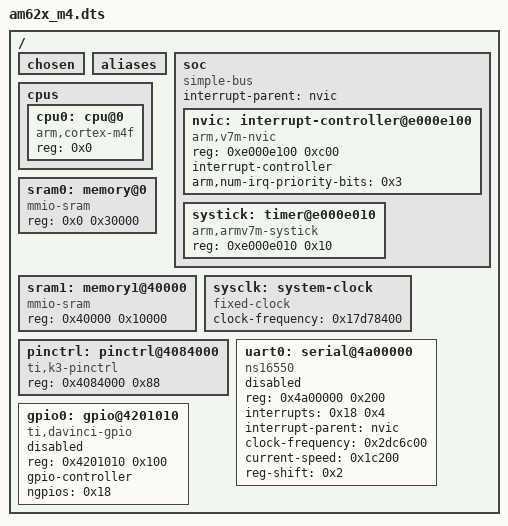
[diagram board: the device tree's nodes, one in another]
/dts-v1/;

/ {
	#address-cells = < 0x1 >;
	#size-cells = < 0x1 >;
	chosen {
	};
	aliases {
	};
	soc {
		#address-cells = < 0x1 >;
		#size-cells = < 0x1 >;
		compatible = "simple-bus";
		interrupt-parent = < &nvic >;
		ranges;
		nvic: interrupt-controller@e000e100 {
			#address-cells = < 0x1 >;
			compatible = "arm,v7m-nvic";
			reg = < 0xe000e100 0xc00 >;
			interrupt-controller;
			#interrupt-cells = < 0x2 >;
			arm,num-irq-priority-bits = < 0x3 >;
			phandle = < 0x1 >;
		};
		systick: timer@e000e010 {
			compatible = "arm,armv7m-systick";
			reg = < 0xe000e010 0x10 >;
			status = "okay";
		};
	};
	cpus {
		#address-cells = < 0x1 >;
		#size-cells = < 0x0 >;
		cpu0: cpu@0 {
			device_type = "cpu";
			compatible = "arm,cortex-m4f";
			reg = < 0x0 >;
		};
	};
	sram0: memory@0 {
		compatible = "mmio-sram";
		reg = < 0x0 0x30000 >;
	};
	sram1: memory1@40000 {
		compatible = "mmio-sram";
		reg = < 0x40000 0x10000 >;
	};
	sysclk: system-clock {
		compatible = "fixed-clock";
		clock-frequency = < 0x17d78400 >;
		#clock-cells = < 0x0 >;
	};
	pinctrl: pinctrl@4084000 {
		compatible = "ti,k3-pinctrl";
		reg = < 0x4084000 0x88 >;
		status = "okay";
	};
	uart0: serial@4a00000 {
		compatible = "ns16550";
		reg = < 0x4a00000 0x200 >;
		interrupts = < 0x18 0x4 >;
		interrupt-parent = < &nvic >;
		clock-frequency = < 0x2dc6c00 >;
		current-speed = < 0x1c200 >;
		reg-shift = < 0x2 >;
		status = "disabled";
	};
	gpio0: gpio@4201010 {
		compatible = "ti,davinci-gpio";
		reg = < 0x4201010 0x100 >;
		gpio-controller;
		#gpio-cells = < 0x2 >;
		ngpios = < 0x18 >;
		status = "disabled";
	};
};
